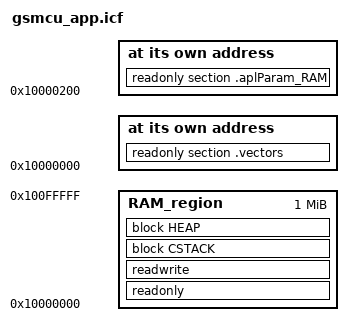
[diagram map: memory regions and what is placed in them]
/*###ICF### Section handled by ICF editor, don't touch! ****/
/*-Editor annotation file-*/
/* IcfEditorFile="$TOOLKIT_DIR$\config\ide\IcfEditor\cortex_v1_0.xml" */
/*-Specials-*/
define symbol __ICFEDIT_intvec_start__ = 0x10000000;
define symbol __ICFEDIT_APL_PARAM_start__ = 0x10000200;
/*-Memory Regions-*/
define symbol __ICFEDIT_region_RAM_start__ = 0x10000000;
define symbol __ICFEDIT_region_RAM_end__   = 0x100FFFFF;
/*-Sizes-*/
define symbol __ICFEDIT_size_cstack__ = 0x1000;
define symbol __ICFEDIT_size_heap__   = 0x1000;
/**** End of ICF editor section. ###ICF###*/

define memory mem with size = 4G;

define region RAM_region   = mem:[from __ICFEDIT_region_RAM_start__   to __ICFEDIT_region_RAM_end__];

define block CSTACK    with alignment = 8, size = __ICFEDIT_size_cstack__   { };
define block HEAP      with alignment = 8, size = __ICFEDIT_size_heap__     { };


place at address mem:__ICFEDIT_intvec_start__ { readonly section .vectors };
place at address mem:__ICFEDIT_APL_PARAM_start__ { readonly section .aplParam_RAM };


//initialize by copy { readwrite };
do not initialize  { section .noinit };


//place in ROM_region   { readonly };
place in RAM_region   { readonly };
place in RAM_region   { readwrite,
                        block CSTACK, block HEAP };
                        
                        
                        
